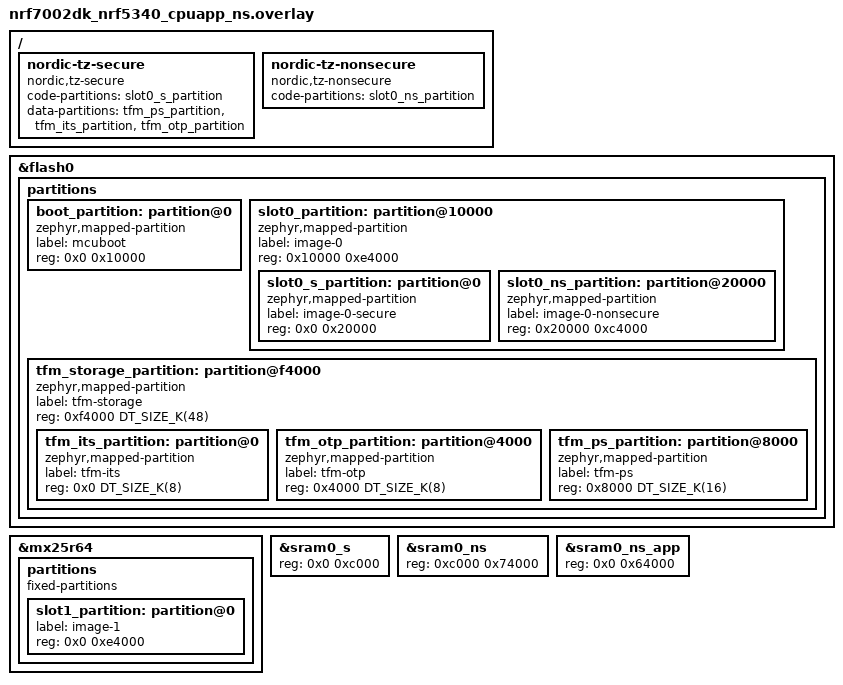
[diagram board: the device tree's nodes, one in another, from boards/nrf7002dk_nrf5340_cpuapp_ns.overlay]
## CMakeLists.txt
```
#
# Copyright (c) 2020 Nordic Semiconductor
#
# SPDX-License-Identifier: LicenseRef-Nordic-5-Clause
#

cmake_minimum_required(VERSION 3.20.0)

find_package(Zephyr REQUIRED HINTS $ENV{ZEPHYR_BASE})
project(aws_iot)

# NORDIC SDK APP START
target_sources(app PRIVATE src/main.c)
target_sources(app PRIVATE src/json_payload/json_payload.c)
# NORDIC SDK APP END

zephyr_include_directories(src)
zephyr_include_directories(src/json_payload)
```

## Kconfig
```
#
# Copyright (c) 2020 Nordic Semiconductor ASA
#
# SPDX-License-Identifier: LicenseRef-Nordic-5-Clause
#

menu "AWS IoT Sample Settings"

config AWS_IOT_SAMPLE_APP_VERSION
	string "Application version"
	default "v1.0.0"
	help
	  Application version reported to AWS IoT.

config AWS_IOT_SAMPLE_JSON_MESSAGE_SIZE_MAX
	int "Maximum size of JSON messages"
	default 200
	help
	  Maximum size of JSON messages that are sent to AWS IoT.

config AWS_IOT_SAMPLE_PUBLICATION_INTERVAL_SECONDS
	int "Interval in seconds that the sample will publish data"
	default 60
	help
	  Time interval between each message publication.

config AWS_IOT_SAMPLE_CONNECTION_RETRY_TIMEOUT_SECONDS
	int "Number of seconds between each AWS IoT connection retry"
	default 30
	help
	  If the connection fails or is lost, the sample tries to reconnect at this interval.

config AWS_IOT_SAMPLE_DEVICE_ID_USE_HW_ID
	bool "Use HW ID as device ID"
	depends on HW_ID_LIBRARY
	help
	  Use the hardware ID as the device ID in the MQTT connection.
	  The hardware ID source is selected by the HW_ID_LIBRARY_SOURCE choice.

module = AWS_IOT_SAMPLE
module-str = AWS IoT sample
source "$(ZEPHYR_BASE)/subsys/logging/Kconfig.template.log_config"

endmenu

menu "Zephyr Kernel"
source "Kconfig.zephyr"
endmenu
```

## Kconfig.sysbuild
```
#
# Copyright (c) 2024 Nordic Semiconductor
#
# SPDX-License-Identifier: LicenseRef-Nordic-5-Clause
#

choice BOOTLOADER
	default BOOTLOADER_MCUBOOT if !BOARD_NATIVE_SIM && \
		!BOARD_NRF54H20DK_NRF54H20_CPUAPP && \
		!BOARD_NRF54LM20DK_NRF54LM20A_CPUAPP && \
		!BOARD_NRF54LM20DK_NRF54LM20B_CPUAPP
endchoice

config WIFI_NRF70
	default y if BOARD_NRF7002DK_NRF5340_CPUAPP_NS || \
		BOARD_NRF54H20DK_NRF54H20_CPUAPP || \
		BOARD_NRF54LM20DK_NRF54LM20A_CPUAPP || \
		BOARD_NRF54LM20DK_NRF54LM20B_CPUAPP

source "share/sysbuild/Kconfig"
```

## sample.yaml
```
sample:
  name: AWS IoT sample
tests:
  sample.net.aws_iot:
    sysbuild: true
    tags:
      - ci_build
      - sysbuild
      - ci_samples_net
    build_only: true
    build_on_all: true
    integration_platforms:
      - nrf9151dk/nrf9151/ns
      - thingy91x/nrf9151/ns
      - native_sim
    platform_allow:
      - nrf9151dk/nrf9151/ns
      - thingy91x/nrf9151/ns
      - native_sim
  sample.net.aws_iot.wifi:
    sysbuild: true
    tags:
      - ci_build
      - sysbuild
      - ci_samples_net
    build_only: true
    build_on_all: true
    integration_platforms:
      - nrf7002dk/nrf5340/cpuapp/ns
      - nrf7120dk/nrf7120/cpuapp/ns
    platform_allow:
      - nrf7002dk/nrf5340/cpuapp/ns
      - nrf7120dk/nrf7120/cpuapp/ns
    extra_args:
      - aws_iot_EXTRA_CONF_FILE="wifi.conf"
  sample.net.aws_iot.nrf7002eb2.wifi:
    sysbuild: true
    tags:
      - ci_build
      - sysbuild
      - ci_samples_net
    build_only: true
    build_on_all: true
    integration_platforms:
      - nrf54lm20dk/nrf54lm20a/cpuapp
      - nrf54lm20dk/nrf54lm20b/cpuapp
    platform_allow:
      - nrf54lm20dk/nrf54lm20a/cpuapp
      - nrf54lm20dk/nrf54lm20b/cpuapp
    extra_args:
      - aws_iot_SHIELD="nrf7002eb2"
      - aws_iot_SNIPPET="nrf70-wifi;wifi-credentials"
      - aws_iot_EXTRA_CONF_FILE="wifi.conf"
```

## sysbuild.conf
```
#
# Copyright (c) 2024 Nordic Semiconductor ASA
#
# SPDX-License-Identifier: LicenseRef-Nordic-5-Clause
#
```

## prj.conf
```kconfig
#
# Copyright (c) 2020 Nordic Semiconductor ASA
#
# SPDX-License-Identifier: LicenseRef-Nordic-5-Clause
#

# General
CONFIG_LOG=y
CONFIG_HW_ID_LIBRARY=y
CONFIG_ASSERT=y
CONFIG_JSON_LIBRARY=y
CONFIG_REBOOT=y

# Heap and stacks
CONFIG_HEAP_MEM_POOL_SIZE=8192
CONFIG_MAIN_STACK_SIZE=4096
CONFIG_SYSTEM_WORKQUEUE_STACK_SIZE=2048

# Network
CONFIG_NETWORKING=y
CONFIG_NET_NATIVE=y
CONFIG_NET_IPV4=y
CONFIG_NET_CONNECTION_MANAGER=y

# AWS IoT library
CONFIG_AWS_IOT=y
CONFIG_AWS_IOT_CLIENT_ID_STATIC="my-thing"
CONFIG_AWS_IOT_BROKER_HOST_NAME="xxx.amazonaws.com"
CONFIG_AWS_IOT_TOPIC_UPDATE_DELTA_SUBSCRIBE=y
CONFIG_AWS_IOT_TOPIC_GET_ACCEPTED_SUBSCRIBE=y
CONFIG_AWS_IOT_TOPIC_GET_REJECTED_SUBSCRIBE=y

# MQTT helper library
CONFIG_MQTT_HELPER=y
CONFIG_MQTT_HELPER_SEC_TAG=201
CONFIG_MQTT_HELPER_LAST_WILL=y
CONFIG_MQTT_HELPER_STACK_SIZE=4096

# MQTT - Maximum MQTT keepalive timeout specified by AWS IoT Core
CONFIG_MQTT_KEEPALIVE=1200
CONFIG_MQTT_CLEAN_SESSION=y
```

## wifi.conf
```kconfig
#
# Copyright (c) 2026 Nordic Semiconductor ASA
#
# SPDX-License-Identifier: LicenseRef-Nordic-5-Clause
#

# Common Wi-Fi + networking + TLS configuration shared by all Wi-Fi builds of
# this sample (nRF70 and nRF71).

# Logging
CONFIG_NET_LOG=y

# Wi-Fi stack
CONFIG_WIFI=y
CONFIG_WIFI_NM_WPA_SUPPLICANT=y
CONFIG_NET_L2_ETHERNET=y
CONFIG_WIFI_NM_WPA_SUPPLICANT_LOG_LEVEL_INF=y

# Wi-Fi credentials. TF-M (_ns) builds use PSA Protected Storage. Non-TF-M
# builds use the Settings subsystem, requiring the wifi-credentials snippet.
CONFIG_WIFI_CREDENTIALS=y
CONFIG_FLASH=y

# Zephyr NET Connection Manager Connectivity layer.
CONFIG_L2_WIFI_CONNECTIVITY=y
CONFIG_L2_WIFI_CONNECTIVITY_AUTO_CONNECT=n
CONFIG_L2_WIFI_CONNECTIVITY_AUTO_DOWN=n

# Networking
CONFIG_NET_SOCKETS=y
CONFIG_NET_SOCKETS_OFFLOAD=n
CONFIG_NET_IPV6=y
CONFIG_NET_UDP=y
CONFIG_NET_TCP=y
CONFIG_NET_DHCPV4=y
CONFIG_NET_CONTEXT_SNDTIMEO=y
CONFIG_NET_CONTEXT_RCVTIMEO=y

# DNS
CONFIG_DNS_RESOLVER=y
CONFIG_NET_SOCKETS_DNS_TIMEOUT=30000
CONFIG_DNS_RESOLVER_AI_MAX_ENTRIES=4

# Shell
CONFIG_SHELL=y
CONFIG_SHELL_CMDS_RESIZE=n
CONFIG_NET_L2_WIFI_SHELL=y

# POSIX API memory optimizations
CONFIG_POSIX_NETWORKING=y
CONFIG_POSIX_FD_MGMT=n
CONFIG_POSIX_MESSAGE_PASSING=n
CONFIG_POSIX_THREAD_THREADS_MAX=0

# Network resource sizing
CONFIG_NET_MAX_CONN=6
CONFIG_NET_MAX_CONTEXTS=5
CONFIG_ZVFS_POLL_MAX=8
CONFIG_NET_PKT_TX_COUNT=6
CONFIG_NET_PKT_RX_COUNT=6
CONFIG_NET_BUF_TX_COUNT=12
CONFIG_NET_BUF_RX_COUNT=6

# Stack sizes
CONFIG_MAIN_STACK_SIZE=6144
CONFIG_SHELL_STACK_SIZE=8192
CONFIG_SYSTEM_WORKQUEUE_STACK_SIZE=8192
CONFIG_NET_TX_STACK_SIZE=4096
CONFIG_NET_RX_STACK_SIZE=2048
CONFIG_NET_SOCKETS_SERVICE_STACK_SIZE=2048

# Heap sizes
CONFIG_HEAP_MEM_POOL_IGNORE_MIN=y
CONFIG_HEAP_MEM_POOL_SIZE=40144
CONFIG_NRF_WIFI_DATA_HEAP_SIZE=65536

# Floating-point printf support (Wi-Fi shell prints PHY TX rate as %f)
CONFIG_CBPRINTF_FP_SUPPORT=y

# NET sockets TLS
CONFIG_NET_SOCKETS_SOCKOPT_TLS=y
CONFIG_NET_SOCKETS_TLS_MAX_CONTEXTS=2

# Generate the device private key and the certificate signing request (CSR) on the device. The
# private key never leaves the device. The device certificate is installed with the TLS
# credentials shell. A credential buffer that fits a certificate chain is needed to install
# the PEM certificates with nrfcredstore.
CONFIG_MQTT_HELPER_CREDENTIALS_KEYGEN=y
CONFIG_TLS_CREDENTIALS_SHELL_CRED_BUF_SIZE=4096
CONFIG_TLS_CREDENTIALS=y
# Persist TLS credentials across reboots.
CONFIG_TLS_CREDENTIALS_BACKEND_PROTECTED_STORAGE=y

# Native network stack
CONFIG_MBEDTLS=y
CONFIG_MBEDTLS_ENABLE_HEAP=y
CONFIG_MBEDTLS_HEAP_SIZE=81920
CONFIG_MBEDTLS_SSL_KEEP_PEER_CERTIFICATE=n
CONFIG_MBEDTLS_SSL_SERVER_NAME_INDICATION=y
# Set MPI (Multiple Precision Integer) size limit to 512 bytes for handling of 4 kb certificates
# in cryptographic operations.
CONFIG_MBEDTLS_MPI_MAX_SIZE=512
# PSA crypto not covered by the ciphersuite: ECDSA for server cert chain verification
CONFIG_PSA_WANT_ALG_ECDSA=y
# TLS crypto via one ciphersuite config
CONFIG_MBEDTLS_CIPHERSUITE_TLS_ECDHE_RSA_WITH_AES_128_GCM_SHA256=y
```

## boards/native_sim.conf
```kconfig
#
# Copyright (c) 2023 Nordic Semiconductor ASA
#
# SPDX-License-Identifier: LicenseRef-Nordic-5-Clause
#

# Networking config
CONFIG_NET_TCP=y
CONFIG_NET_UDP=y
CONFIG_NET_SOCKETS=y
CONFIG_POSIX_API=y
CONFIG_NET_SOCKETS_SOCKOPT_TLS=y
CONFIG_NET_PKT_RX_COUNT=32
CONFIG_NET_PKT_TX_COUNT=32
CONFIG_NET_BUF_RX_COUNT=32
CONFIG_NET_BUF_TX_COUNT=32
CONFIG_NET_IF_UNICAST_IPV6_ADDR_COUNT=3
CONFIG_NET_IF_MCAST_IPV6_ADDR_COUNT=4
CONFIG_NET_MAX_CONTEXTS=10
CONFIG_NET_L2_ETHERNET=y
CONFIG_NET_CONTEXT_SNDTIMEO=y

CONFIG_ETH_NATIVE_TAP=y

# Network driver config
CONFIG_TEST_RANDOM_GENERATOR=y

# TLS configuration
CONFIG_MBEDTLS=y
CONFIG_MBEDTLS_ENABLE_HEAP=y
CONFIG_MBEDTLS_HEAP_SIZE=40000
CONFIG_MBEDTLS_SSL_MAX_CONTENT_LEN=7168
CONFIG_MBEDTLS_PEM_PARSE_C=y
CONFIG_MBEDTLS_PEM_WRITE_C=y
CONFIG_MBEDTLS_CIPHERSUITE_TLS_ECDHE_RSA_WITH_AES_128_CBC_SHA256=y

# DNS
CONFIG_DNS_RESOLVER=y
CONFIG_DNS_SERVER_IP_ADDRESSES=y
CONFIG_DNS_SERVER1="8.8.8.8"
CONFIG_DNS_RESOLVER_MAX_SERVERS=2

# Network address config
CONFIG_NET_CONFIG_SETTINGS=y
CONFIG_NET_CONFIG_NEED_IPV4=y
CONFIG_NET_CONFIG_MY_IPV4_ADDR="192.0.2.1"
CONFIG_NET_CONFIG_MY_IPV4_GW="192.0.2.2"
```

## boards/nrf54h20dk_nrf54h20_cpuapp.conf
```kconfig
#
# Copyright (c) 2024 Nordic Semiconductor ASA
#
# SPDX-License-Identifier: LicenseRef-Nordic-5-Clause
#

# Wi-Fi
CONFIG_WIFI=y
CONFIG_WIFI_NRF70=y
CONFIG_WIFI_CREDENTIALS=y
# Needed for Wi-Fi credentials
CONFIG_FLASH=y
CONFIG_FLASH_PAGE_LAYOUT=y
CONFIG_FLASH_MAP=y
CONFIG_ZMS=y
CONFIG_SETTINGS=y

# WPA supplicant
CONFIG_WIFI_NM_WPA_SUPPLICANT=y
CONFIG_WIFI_NM_WPA_SUPPLICANT_LOG_LEVEL_INF=y

# Networking
CONFIG_NET_L2_ETHERNET=y
CONFIG_NET_SOCKETS=y
CONFIG_NET_IPV6=y
CONFIG_NET_UDP=y
CONFIG_NET_TCP=y
CONFIG_NET_DHCPV4=y
CONFIG_DNS_RESOLVER=y
CONFIG_DNS_RESOLVER_AI_MAX_ENTRIES=4

# NET sockets
CONFIG_NET_UDP=y
CONFIG_NET_TCP=y
CONFIG_NET_MAX_CONN=6
CONFIG_NET_MAX_CONTEXTS=5
CONFIG_NET_SOCKETS_POLL_MAX=8
CONFIG_NET_SOCKETS_OFFLOAD=n
CONFIG_NET_DHCPV4=y
CONFIG_NET_CONTEXT_SNDTIMEO=y
CONFIG_NET_CONTEXT_RCVTIMEO=y
CONFIG_NET_MAX_CONTEXTS=3

# NET buffers
CONFIG_NET_PKT_TX_COUNT=6
CONFIG_NET_PKT_RX_COUNT=6
CONFIG_NET_BUF_TX_COUNT=12
CONFIG_NET_BUF_RX_COUNT=6
CONFIG_NRF70_RX_NUM_BUFS=6
CONFIG_NET_PKT_BUF_RX_DATA_POOL_SIZE=4096
CONFIG_NET_PKT_BUF_TX_DATA_POOL_SIZE=4096
CONFIG_NRF70_MAX_TX_AGGREGATION=1

# MQTT
CONFIG_MQTT_HELPER_PROVISION_CERTIFICATES=y

# Kernel options
CONFIG_POSIX_NETWORKING=y
CONFIG_ZVFS_OPEN_MAX=21

# Shell
CONFIG_SHELL=y
CONFIG_SHELL_CMDS_RESIZE=n
CONFIG_NET_L2_WIFI_SHELL=y

# TLS
CONFIG_NET_SOCKETS_SOCKOPT_TLS=y
CONFIG_NET_SOCKETS_TLS_MAX_CONTEXTS=1
CONFIG_MBEDTLS=y
CONFIG_MBEDTLS_ENABLE_HEAP=y
CONFIG_MBEDTLS_SSL_KEEP_PEER_CERTIFICATE=n
CONFIG_MBEDTLS_SSL_SERVER_NAME_INDICATION=y
CONFIG_TLS_CREDENTIALS=y
CONFIG_TLS_CREDENTIALS_BACKEND_VOLATILE=y

# Zephyr NET Connection Manager Connectivity layer.
CONFIG_L2_WIFI_CONNECTIVITY=y
CONFIG_L2_WIFI_CONNECTIVITY_AUTO_CONNECT=y
CONFIG_L2_WIFI_CONNECTIVITY_AUTO_DOWN=n

# Stack sizes
CONFIG_NET_CONNECTION_MANAGER_MONITOR_STACK_SIZE=5000
CONFIG_MAIN_STACK_SIZE=6144
CONFIG_NET_TX_STACK_SIZE=2048
CONFIG_NET_RX_STACK_SIZE=2048
CONFIG_NET_MGMT_EVENT_STACK_SIZE=1024
CONFIG_SYSTEM_WORKQUEUE_STACK_SIZE=3100
CONFIG_NRF70_IRQ_WQ_STACK_SIZE=1024
CONFIG_NRF70_BH_WQ_STACK_SIZE=2300
CONFIG_SHELL_STACK_SIZE=4400
CONFIG_ISR_STACK_SIZE=512

# Heap sizes
CONFIG_HEAP_MEM_POOL_IGNORE_MIN=y
CONFIG_MBEDTLS_HEAP_SIZE=45000
CONFIG_HEAP_MEM_POOL_SIZE=32000
CONFIG_NRF_WIFI_CTRL_HEAP_SIZE=20000
CONFIG_NRF_WIFI_DATA_HEAP_SIZE=40000

# POSIX API memory optimizations
CONFIG_POSIX_FD_MGMT=n
CONFIG_POSIX_MESSAGE_PASSING=n
CONFIG_POSIX_THREAD_THREADS_MAX=0

# Floating-point printf support
CONFIG_CBPRINTF_FP_SUPPORT=y
```

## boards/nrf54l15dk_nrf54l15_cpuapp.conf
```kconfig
#
# Copyright (c) 2024 Nordic Semiconductor ASA
#
# SPDX-License-Identifier: LicenseRef-Nordic-5-Clause
#

# Wi-Fi
CONFIG_WIFI=y
CONFIG_WIFI_NRF70=y
CONFIG_WIFI_CREDENTIALS=y
# Needed for Wi-Fi credentials
CONFIG_FLASH=y
CONFIG_FLASH_PAGE_LAYOUT=y
CONFIG_FLASH_MAP=y
CONFIG_ZMS=y
CONFIG_SETTINGS=y

# WPA supplicant
CONFIG_WIFI_NM_WPA_SUPPLICANT=y
CONFIG_WIFI_NM_WPA_SUPPLICANT_LOG_LEVEL_INF=y

# Networking
CONFIG_NET_L2_ETHERNET=y
CONFIG_NET_SOCKETS=y
CONFIG_NET_IPV6=y
CONFIG_NET_UDP=y
CONFIG_NET_TCP=y
CONFIG_NET_DHCPV4=y
CONFIG_DNS_RESOLVER=y
CONFIG_DNS_RESOLVER_AI_MAX_ENTRIES=4

# NET sockets
CONFIG_NET_UDP=y
CONFIG_NET_TCP=y
CONFIG_NET_MAX_CONN=6
CONFIG_NET_MAX_CONTEXTS=5
CONFIG_ZVFS_POLL_MAX=8
CONFIG_NET_SOCKETS_OFFLOAD=n
CONFIG_NET_DHCPV4=y
CONFIG_NET_CONTEXT_SNDTIMEO=y
CONFIG_NET_CONTEXT_RCVTIMEO=y
CONFIG_NET_MAX_CONTEXTS=3

# NET buffers
CONFIG_NET_PKT_TX_COUNT=6
CONFIG_NET_PKT_RX_COUNT=6
CONFIG_NET_BUF_TX_COUNT=12
CONFIG_NET_BUF_RX_COUNT=6
CONFIG_NRF70_RX_NUM_BUFS=6
CONFIG_NET_PKT_BUF_RX_DATA_POOL_SIZE=4096
CONFIG_NET_PKT_BUF_TX_DATA_POOL_SIZE=4096
CONFIG_NRF70_MAX_TX_AGGREGATION=1

# MQTT
CONFIG_MQTT_HELPER_PROVISION_CERTIFICATES=y

# Kernel options
CONFIG_POSIX_NETWORKING=y

# Shell
CONFIG_SHELL=y
CONFIG_SHELL_CMDS_RESIZE=n
CONFIG_NET_L2_WIFI_SHELL=y

# TLS
CONFIG_NET_SOCKETS_SOCKOPT_TLS=y
CONFIG_NET_SOCKETS_TLS_MAX_CONTEXTS=1
CONFIG_MBEDTLS=y
CONFIG_MBEDTLS_ENABLE_HEAP=y
CONFIG_MBEDTLS_SSL_KEEP_PEER_CERTIFICATE=n
CONFIG_MBEDTLS_SSL_SERVER_NAME_INDICATION=y
CONFIG_TLS_CREDENTIALS=y
CONFIG_TLS_CREDENTIALS_BACKEND_VOLATILE=y

# Zephyr NET Connection Manager Connectivity layer.
CONFIG_L2_WIFI_CONNECTIVITY=y
CONFIG_L2_WIFI_CONNECTIVITY_AUTO_CONNECT=y
CONFIG_L2_WIFI_CONNECTIVITY_AUTO_DOWN=n

# Stack sizes
CONFIG_MAIN_STACK_SIZE=6144
CONFIG_NET_TX_STACK_SIZE=2048
CONFIG_NET_RX_STACK_SIZE=2048
CONFIG_NET_MGMT_EVENT_STACK_SIZE=1024
CONFIG_SYSTEM_WORKQUEUE_STACK_SIZE=3100
CONFIG_NRF70_IRQ_WQ_STACK_SIZE=1024
CONFIG_NRF70_BH_WQ_STACK_SIZE=2300
CONFIG_SHELL_STACK_SIZE=4400
CONFIG_ISR_STACK_SIZE=512

# Heap sizes
CONFIG_HEAP_MEM_POOL_IGNORE_MIN=y
CONFIG_MBEDTLS_HEAP_SIZE=45000
CONFIG_HEAP_MEM_POOL_SIZE=32000
CONFIG_NRF_WIFI_CTRL_HEAP_SIZE=20000
CONFIG_NRF_WIFI_DATA_HEAP_SIZE=40000

# POSIX API memory optimizations
CONFIG_POSIX_FD_MGMT=n
CONFIG_POSIX_MESSAGE_PASSING=n
CONFIG_POSIX_THREAD_THREADS_MAX=0

# Floating-point printf support
CONFIG_CBPRINTF_FP_SUPPORT=y
```

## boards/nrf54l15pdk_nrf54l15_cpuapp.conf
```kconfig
#
# Copyright (c) 2024 Nordic Semiconductor ASA
#
# SPDX-License-Identifier: LicenseRef-Nordic-5-Clause
#

# Wi-Fi
CONFIG_WIFI=y
CONFIG_WIFI_NRF700X=y

# WPA supplicant
CONFIG_WPA_SUPP=y
CONFIG_WPA_SUPP_LOG_LEVEL_INF=y
CONFIG_NET_L2_WIFI_SHELL=y

# Networking
CONFIG_NET_L2_ETHERNET=y
CONFIG_NETWORKING=y
CONFIG_NET_SOCKETS=y
CONFIG_NET_IPV6=y
CONFIG_NET_IPV4=y
CONFIG_NET_UDP=y
CONFIG_NET_TCP=y
CONFIG_NET_DHCPV4=y
CONFIG_DNS_RESOLVER=y
CONFIG_DNS_RESOLVER_AI_MAX_ENTRIES=4




# NET sockets
CONFIG_NET_UDP=y
CONFIG_NET_TCP=y
CONFIG_NET_MAX_CONN=6
CONFIG_NET_MAX_CONTEXTS=5
CONFIG_NET_SOCKETS_POLL_MAX=8
CONFIG_NET_SOCKETS_OFFLOAD=n
CONFIG_NET_DHCPV4=y
CONFIG_NET_CONTEXT_SNDTIMEO=y
CONFIG_NET_CONTEXT_RCVTIMEO=y

# Below section is the primary contributor to SRAM and is currently
# tuned for performance, but this will be revisited in the future.
CONFIG_NET_BUF_RX_COUNT=16
CONFIG_NET_BUF_TX_COUNT=16
CONFIG_NET_BUF_DATA_SIZE=128
CONFIG_NRF700X_RX_NUM_BUFS=16
CONFIG_NRF700X_MAX_TX_AGGREGATION=4
# nRF700x is main consumer: (16 + 8) * 1600 = ~40KB + ~40KB control path (experimental)
CONFIG_NET_TC_TX_COUNT=1

# MQTT
CONFIG_MQTT_HELPER_PROVISION_CERTIFICATES=y

# Kernel options
CONFIG_REBOOT=y
CONFIG_POSIX_API=y
CONFIG_POSIX_MAX_FDS=25

# Shell
CONFIG_SHELL=y
CONFIG_SHELL_CMDS_RESIZE=n

# Logging
CONFIG_NET_CONFIG_AUTO_INIT=n

# TLS
CONFIG_NET_SOCKETS_SOCKOPT_TLS=y
CONFIG_NET_SOCKETS_TLS_MAX_CONTEXTS=2
CONFIG_NRF_SECURITY=y
CONFIG_MBEDTLS=y
CONFIG_MBEDTLS_ENABLE_HEAP=y
CONFIG_MBEDTLS_SSL_KEEP_PEER_CERTIFICATE=n
CONFIG_MBEDTLS_SSL_SERVER_NAME_INDICATION=y
CONFIG_TLS_CREDENTIALS=y
CONFIG_TLS_CREDENTIALS_BACKEND_VOLATILE=y

# Stack sizes
CONFIG_NET_CONNECTION_MANAGER_MONITOR_STACK_SIZE=4096
CONFIG_NET_TX_STACK_SIZE=2048
CONFIG_NET_RX_STACK_SIZE=2048
CONFIG_NET_MGMT_EVENT_STACK_SIZE=1024
CONFIG_SYSTEM_WORKQUEUE_STACK_SIZE=2300
CONFIG_NRF700X_IRQ_WQ_STACK_SIZE=1024
CONFIG_NRF700X_BH_WQ_STACK_SIZE=2300
CONFIG_MQTT_HELPER_STACK_SIZE=4096
CONFIG_SHELL_STACK_SIZE=4400

# Heap sizes
CONFIG_COMMON_LIBC_MALLOC_ARENA_SIZE=21808
CONFIG_MBEDTLS_HEAP_SIZE=54920
CONFIG_HEAP_MEM_POOL_SIZE=80000

# Bootloader requirements
CONFIG_BOOTLOADER_MCUBOOT=y
CONFIG_FLASH=y
CONFIG_FLASH_PAGE_LAYOUT=y
CONFIG_FLASH_MAP=y
CONFIG_STREAM_FLASH=y
CONFIG_STREAM_FLASH_ERASE=y
CONFIG_IMG_MANAGER=y
CONFIG_MCUBOOT_IMG_MANAGER=y
CONFIG_FW_INFO_OFFSET=0x800

# AWS FOTA
CONFIG_AWS_FOTA=y
CONFIG_FOTA_DOWNLOAD=y
CONFIG_DFU_TARGET=y

# Download client (needed by AWS FOTA)
CONFIG_DOWNLOAD_CLIENT=y
CONFIG_DOWNLOAD_CLIENT_STACK_SIZE=4096
CONFIG_DOWNLOAD_CLIENT_BUF_SIZE=4096
CONFIG_DOWNLOAD_CLIENT_HTTP_FRAG_SIZE_4096=y

# Disable connection manager
CONFIG_NET_CONNECTION_MANAGER=n
```

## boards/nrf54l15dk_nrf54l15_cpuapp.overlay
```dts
/*
 * Copyright (c) 2024 Nordic Semiconductor ASA
 *
 * SPDX-License-Identifier: LicenseRef-Nordic-5-Clause
 */

&rram_controller {
	/delete-node/ cpuflpr_sram;
	/delete-node/ cpuflpr_rram;
};

/* Adjust the cpuapp_sram to include the freed up cpuflpr_sram */
&cpuapp_sram {
	reg = <0x20000000 DT_SIZE_K(256)>;
	ranges = <0x0 0x20000000 0x20040000>;
};

/* Adjust the cpuapp_rram to include the freed up cpuflpr_rram */
&cpuapp_rram {
	reg = <0x0 DT_SIZE_K(1524)>;
};
```

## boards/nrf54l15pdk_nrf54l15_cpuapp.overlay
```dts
/*
 * Copyright (c) 2024 Nordic Semiconductor ASA
 *
 * SPDX-License-Identifier: LicenseRef-Nordic-5-Clause
 */

/ {
	/* Configure the partition manager to use the mx25r64 external flash memory. */
	chosen {
		nordic,pm-ext-flash = &mx25r64;
	};
};

&mx25r64 {
	status = "okay";
};

/* Restore full RRAM and SRAM space - by default some parts are dedicated to VPR */
&cpuapp_rram {
	reg = <0x0 DT_SIZE_K(1524)>;
};

&cpuapp_sram {
	reg = <0x20000000 DT_SIZE_K(256)>;
	ranges = <0x0 0x20000000  0x40000>;
};
```

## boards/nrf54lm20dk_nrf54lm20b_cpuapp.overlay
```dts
/*
 * Copyright (c) 2026 Nordic Semiconductor ASA
 *
 * SPDX-License-Identifier: LicenseRef-Nordic-5-Clause
 */

/delete-node/ &boot_partition;
/delete-node/ &slot0_partition;
/delete-node/ &slot1_partition;
/delete-node/ &storage_partition;

&cpuapp_rram {
	partitions {
		slot0_partition: partition@0 {
			compatible = "zephyr,mapped-partition";
			label = "image-0";
			reg = <0x0 0x1f5000>;
		};

		storage_partition: partition@1f5000 {
			compatible = "zephyr,mapped-partition";
			label = "storage";
			reg = <0x1f5000 0x8000>;
		};
	};
};
```

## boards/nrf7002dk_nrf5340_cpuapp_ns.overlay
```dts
/*
 * Copyright (c) 2023 Nordic Semiconductor ASA
 *
 * SPDX-License-Identifier: LicenseRef-Nordic-5-Clause
 */

/delete-node/ &boot_partition;
/delete-node/ &slot0_partition;
/delete-node/ &slot1_partition;
/delete-node/ &tfm_its_partition;
/delete-node/ &tfm_otp_partition;
/delete-node/ &tfm_ps_partition;
/delete-node/ &storage_partition;

&flash0 {
	partitions {
		boot_partition: partition@0 {
			compatible = "zephyr,mapped-partition";
			label = "mcuboot";
			reg = <0x0 0x10000>;
		};

		slot0_partition: partition@10000 {
			compatible = "zephyr,mapped-partition";
			label = "image-0";
			reg = <0x10000 0xe4000>;
			ranges = <0x0 0x10000 0xe4000>;
			#address-cells = <1>;
			#size-cells = <1>;

			slot0_s_partition: partition@0 {
				compatible = "zephyr,mapped-partition";
				label = "image-0-secure";
				reg = <0x0 0x20000>;
			};

			slot0_ns_partition: partition@20000 {
				compatible = "zephyr,mapped-partition";
				label = "image-0-nonsecure";
				reg = <0x20000 0xc4000>;
			};
		};

		tfm_storage_partition: partition@f4000 {
			compatible = "zephyr,mapped-partition";
			label = "tfm-storage";
			reg = <0xf4000 DT_SIZE_K(48)>;
			ranges = <0x0 0xf4000 DT_SIZE_K(48)>;
			#address-cells = <1>;
			#size-cells = <1>;

			tfm_its_partition: partition@0 {
				compatible = "zephyr,mapped-partition";
				label = "tfm-its";
				reg = <0x0 DT_SIZE_K(8)>;
			};

			tfm_otp_partition: partition@4000 {
				compatible = "zephyr,mapped-partition";
				label = "tfm-otp";
				reg = <0x4000 DT_SIZE_K(8)>;
			};

			tfm_ps_partition: partition@8000 {
				compatible = "zephyr,mapped-partition";
				label = "tfm-ps";
				reg = <0x8000 DT_SIZE_K(16)>;
			};
		};
	};
};

&mx25r64 {
	status = "okay";

	partitions {
		compatible = "fixed-partitions";
		#address-cells = <1>;
		#size-cells = <1>;

		slot1_partition: partition@0 {
			label = "image-1";
			reg = <0x0 0xe4000>;
		};
	};
};

/*
 * TrustZone SRAM split from devicetree (region_defs.h for TF-M). The secure image uses
 * 48 KiB (0xc000) at the base of cpuapp SRAM (&sram0_s); NS RAM begins at 0x20000000 + 0xc000.
 * &sram0_ns spans 0x74000 bytes; &sram0_ns_app is 0x64000 because the top 0x10000 (64 KiB)
 * within that NS window is sram0_shared for application/network-core IPC
 * (nrf5340_shared_sram_partition.dtsi), i.e. 0x64000 + 0x10000 == 0x74000.
 */
&sram0_s {
	reg = <0x0 0xc000>;
};

&sram0_ns {
	reg = <0xc000 0x74000>;
	ranges = <0x0 0xc000 0x74000>;
};

&sram0_ns_app {
	reg = <0x0 0x64000>;
};

/ {
	/delete-node/ nordic-tz-secure;
	/delete-node/ nordic-tz-nonsecure;

	nordic-tz-secure {
		compatible = "nordic,tz-secure";
		code-partitions = <&slot0_s_partition>;
		data-partitions = <&tfm_ps_partition>,
				  <&tfm_its_partition>,
				  <&tfm_otp_partition>;
	};

	nordic-tz-nonsecure {
		compatible = "nordic,tz-nonsecure";
		code-partitions = <&slot0_ns_partition>;
	};
};
```

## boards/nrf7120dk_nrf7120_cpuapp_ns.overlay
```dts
/*
 * Copyright (c) 2026 Nordic Semiconductor ASA
 *
 * SPDX-License-Identifier: LicenseRef-Nordic-5-Clause
 */

&cpuapp_mram {
	/delete-node/ partitions;
};

&cpuapp_mram {
	/*
	 * Default NVM layout on NRF7120 NS Application MCU with MCUBoot:
	 *
	 * 0x0000_0000 Boot Partition (64 KB)
	 *
	 * 0x0001_0000 Primary image area (1952 KB):
	 *   - 0x0001_0000 Secure image primary (192 KB)
	 *   - 0x0004_0000 Non-secure image primary (1760 KB)
	 *
	 * 0x001F_8000 Secondary image area (1952 KB):
	 *   - 0x001F_8000 Secure image secondary (192 KB)
	 *   - 0x0022_8000 Non-secure image secondary (1760 KB)
	 *
	 * 0x003E_0000 Protected Storage Area (16 KB)
	 * 0x003E_4000 Internal Trusted Storage Area (16 KB)
	 * 0x003E_8000 OTP / NV counters area (8 KB)
	 *
	 * 0x003E_A000 Non-secure storage, used when built with NRF_NS_STORAGE=ON,
	 *             otherwise unused (68 KB)
	 */
	partitions {
		#address-cells = <1>;
		#size-cells = <1>;
		ranges;

		boot_partition: partition@0 {
			compatible = "zephyr,mapped-partition";
			label = "mcuboot";
			reg = <0x00000000 DT_SIZE_K(64)>;
		};

		slot0_partition: partition@10000 {
			compatible = "zephyr,mapped-partition";
			label = "image-0";
			reg = <0x00010000 DT_SIZE_K(1952)>;
			ranges = <0x0 0x00010000 DT_SIZE_K(1952)>;
			#address-cells = <1>;
			#size-cells = <1>;

			slot0_s_partition: partition@0 {
				compatible = "zephyr,mapped-partition";
				label = "image-0-secure";
				reg = <0x0 DT_SIZE_K(192)>;
			};

			slot0_ns_partition: partition@30000 {
				compatible = "zephyr,mapped-partition";
				label = "image-0-nonsecure";
				reg = <0x30000 DT_SIZE_K(1760)>;
			};
		};

		slot1_partition: partition@1f8000 {
			compatible = "zephyr,mapped-partition";
			label = "image-1";
			reg = <0x001f8000 DT_SIZE_K(1952)>;
			ranges = <0x0 0x001f8000 DT_SIZE_K(1952)>;
			#address-cells = <1>;
			#size-cells = <1>;

			slot1_s_partition: partition@0 {
				compatible = "zephyr,mapped-partition";
				label = "image-1-secure";
				reg = <0x0 DT_SIZE_K(192)>;
			};

			slot1_ns_partition: partition@30000 {
				compatible = "zephyr,mapped-partition";
				label = "image-1-nonsecure";
				reg = <0x30000 DT_SIZE_K(1760)>;
			};
		};

		tfm_ps_partition: partition@3e0000 {
			compatible = "zephyr,mapped-partition";
			label = "tfm-ps";
			reg = <0x003e0000 DT_SIZE_K(16)>;
		};

		tfm_its_partition: partition@3e4000 {
			compatible = "zephyr,mapped-partition";
			label = "tfm-its";
			reg = <0x003e4000 DT_SIZE_K(16)>;
		};

		tfm_otp_partition: partition@3e8000 {
			compatible = "zephyr,mapped-partition";
			label = "tfm-otp";
			reg = <0x003e8000 DT_SIZE_K(8)>;
		};

		storage_partition: partition@3ea000 {
			compatible = "zephyr,mapped-partition";
			label = "storage";
			reg = <0x003ea000 DT_SIZE_K(68)>;
		};
	};
};

/ {
	chosen {
		zephyr,code-partition = &slot0_ns_partition;
	};
};
```

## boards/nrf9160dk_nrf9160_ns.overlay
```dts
/*
 * Copyright (c) 2023 Nordic Semiconductor ASA
 *
 * SPDX-License-Identifier: LicenseRef-Nordic-5-Clause
 */

#include <samples/cellular/nrf91_bootloader_partitions.dtsi>

#include <samples/cellular/nrf91_sram_partitions.dtsi>

/* Enable uart1 for tracing. */
&uart1 {
	status = "okay";
	current-speed = <1000000>;
};

/ {
	chosen {
		nordic,modem-trace-uart = &uart1;
	};
};

/* Increase modem (shared) memory and add trace partition. */
&sram0_ns_modem {
	reg = <0x0 0x8800>;
	ranges = <0x0 0x0 0x8800>;

	cpucell_cpuapp_ipc_shm_trace: sram0_ns_modem@4800 {
		/* Modem trace memory */
		reg = <0x4800 0x4000>;
	};
};

/* Delete Non-Secure application memory so we can move and shrink it. */
/delete-node/ &sram0_ns_app;

&sram0_ns {
	sram0_ns_app: sram0_ns@8800 {
		/* Redefine smaller Non-Secure application memory. */
		reg = <0x8800 0x2f800>;
	};
};
```

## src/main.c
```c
/*
 * Copyright (c) 2020 Nordic Semiconductor ASA
 *
 * SPDX-License-Identifier: LicenseRef-Nordic-5-Clause
 */

#include <zephyr/kernel.h>
#include <zephyr/sys/reboot.h>
#include <zephyr/dfu/mcuboot.h>
#include <zephyr/logging/log.h>
#include <zephyr/logging/log_ctrl.h>
#include <zephyr/net/conn_mgr_connectivity.h>
#include <net/aws_iot.h>
#include <stdio.h>
#include <stdlib.h>
#include <hw_id.h>
#include <modem/modem_info.h>

#include "json_payload.h"

/* Register log module */
LOG_MODULE_REGISTER(aws_iot_sample, CONFIG_AWS_IOT_SAMPLE_LOG_LEVEL);

/* Macros used to subscribe to specific Zephyr NET management events. */
#define L4_EVENT_MASK (NET_EVENT_L4_DNS_READY | NET_EVENT_L4_DNS_LOST)
#define CONN_LAYER_EVENT_MASK (NET_EVENT_CONN_IF_FATAL_ERROR)

#define MODEM_FIRMWARE_VERSION_SIZE_MAX 50

/* Application specific topics. */
#define MY_CUSTOM_TOPIC_1 "my-custom-topic/example"
#define MY_CUSTOM_TOPIC_2 "my-custom-topic/example_2"

/* Macro called upon a fatal error, reboots the device. */
#define FATAL_ERROR()					\
	LOG_ERR("Fatal error! Rebooting the device.");	\
	LOG_PANIC();					\
	IF_ENABLED(CONFIG_REBOOT, (sys_reboot(0)))

/* Variable used to store the device's hardware ID. */
static char hw_id[HW_ID_LEN];

/* Forward declarations. */
static void shadow_update_work_fn(struct k_work *work);
static void connect_work_fn(struct k_work *work);
static void aws_iot_event_handler(const struct aws_iot_evt *const evt);

/* Work items used to control some aspects of the sample. */
static K_WORK_DELAYABLE_DEFINE(shadow_update_work, shadow_update_work_fn);
static K_WORK_DELAYABLE_DEFINE(connect_work, connect_work_fn);

/* Static functions */

static int app_topics_subscribe(void)
{
	int err;
	static const struct mqtt_topic topic_list[] = {
		{
			.topic.utf8 = MY_CUSTOM_TOPIC_1,
			.topic.size = sizeof(MY_CUSTOM_TOPIC_1) - 1,
			.qos = MQTT_QOS_1_AT_LEAST_ONCE,
		},
		{
			.topic.utf8 = MY_CUSTOM_TOPIC_2,
			.topic.size = sizeof(MY_CUSTOM_TOPIC_2) - 1,
			.qos = MQTT_QOS_1_AT_LEAST_ONCE,
		}
	};

	err = aws_iot_application_topics_set(topic_list, ARRAY_SIZE(topic_list));
	if (err) {
		LOG_ERR("aws_iot_application_topics_set, error: %d", err);
		FATAL_ERROR();
		return err;
	}

	return 0;
}

static int aws_iot_client_init(void)
{
	int err;

	err = aws_iot_init(aws_iot_event_handler);
	if (err) {
		LOG_ERR("AWS IoT library could not be initialized, error: %d", err);
		FATAL_ERROR();
		return err;
	}

	/* Add application specific non-shadow topics to the AWS IoT library.
	 * These topics will be subscribed to when connecting to the broker.
	 */
	err = app_topics_subscribe();
	if (err) {
		LOG_ERR("Adding application specific topics failed, error: %d", err);
		FATAL_ERROR();
		return err;
	}

	return 0;
}

/* System Workqueue handlers. */

static void shadow_update_work_fn(struct k_work *work)
{
	int err;
	char message[CONFIG_AWS_IOT_SAMPLE_JSON_MESSAGE_SIZE_MAX] = { 0 };
	struct payload payload = {
		.state.reported.uptime = k_uptime_get(),
		.state.reported.app_version = CONFIG_AWS_IOT_SAMPLE_APP_VERSION,
	};
	struct aws_iot_data tx_data = {
		.qos = MQTT_QOS_0_AT_MOST_ONCE,
		.topic.type = AWS_IOT_SHADOW_TOPIC_UPDATE,
	};

	if (IS_ENABLED(CONFIG_MODEM_INFO)) {
		char modem_version_temp[MODEM_FIRMWARE_VERSION_SIZE_MAX];

		err = modem_info_get_fw_version(modem_version_temp,
						ARRAY_SIZE(modem_version_temp));
		if (err) {
			LOG_ERR("modem_info_get_fw_version, error: %d", err);
			FATAL_ERROR();
			return;
		}

		payload.state.reported.modem_version = modem_version_temp;
	}

	err = json_payload_construct(message, sizeof(message), &payload);
	if (err) {
		LOG_ERR("json_payload_construct, error: %d", err);
		FATAL_ERROR();
		return;
	}

	tx_data.ptr = message;
	tx_data.len = strlen(message);

	LOG_INF("Publishing message: %s to AWS IoT shadow", message);

	err = aws_iot_send(&tx_data);
	if (err) {
		LOG_ERR("aws_iot_send, error: %d", err);
		FATAL_ERROR();
		return;
	}

	(void)k_work_reschedule(&shadow_update_work,
				K_SECONDS(CONFIG_AWS_IOT_SAMPLE_PUBLICATION_INTERVAL_SECONDS));
}

static void connect_work_fn(struct k_work *work)
{
	int err;
	const struct aws_iot_config config = {
		.client_id = hw_id,
	};

	LOG_INF("Connecting to AWS IoT");

	err = aws_iot_connect(&config);
	if (err == -EAGAIN) {
		LOG_INF("Connection attempt timed out, "
			"Next connection retry in %d seconds",
			CONFIG_AWS_IOT_SAMPLE_CONNECTION_RETRY_TIMEOUT_SECONDS);

		(void)k_work_reschedule(&connect_work,
				K_SECONDS(CONFIG_AWS_IOT_SAMPLE_CONNECTION_RETRY_TIMEOUT_SECONDS));
	} else if (err) {
		LOG_ERR("aws_iot_connect, error: %d", err);
		FATAL_ERROR();
	}
}

/* Functions that are executed on specific connection-related events. */

static void on_aws_iot_evt_connected(const struct aws_iot_evt *const evt)
{
	(void)k_work_cancel_delayable(&connect_work);

	/* If persistent session is enabled, the AWS IoT library will not subscribe to any topics.
	 * Topics from the last session will be used.
	 */
	if (evt->data.persistent_session) {
		LOG_WRN("Persistent session is enabled, using subscriptions "
			"from the previous session");
	}

	/* Mark image as working to avoid reverting to the former image after a reboot. */
	if (IS_ENABLED(CONFIG_BOOTLOADER_MCUBOOT)) {
		boot_write_img_confirmed();
	}

	/* Start sequential updates to AWS IoT. */
	(void)k_work_reschedule(&shadow_update_work, K_NO_WAIT);
}

static void on_aws_iot_evt_disconnected(void)
{
	(void)k_work_cancel_delayable(&shadow_update_work);
	(void)k_work_reschedule(&connect_work, K_SECONDS(5));
}

static void on_aws_iot_evt_fota_done(const struct aws_iot_evt *const evt)
{
	int err;

	/* Tear down MQTT connection. */
	(void)aws_iot_disconnect();
	(void)k_work_cancel_delayable(&connect_work);

	/* If modem FOTA has been carried out, the modem needs to be reinitialized.
	 * This is carried out by bringing the network interface down/up.
	 */
	if (evt->data.image & DFU_TARGET_IMAGE_TYPE_ANY_MODEM) {
		LOG_INF("Modem FOTA done, reinitializing the modem");

		err = conn_mgr_all_if_down(true);
		if (err) {
			LOG_ERR("conn_mgr_all_if_down, error: %d", err);
			FATAL_ERROR();
			return;
		}

		err = conn_mgr_all_if_up(true);
		if (err) {
			LOG_ERR("conn_mgr_all_if_up, error: %d", err);
			FATAL_ERROR();
			return;
		}

		err = conn_mgr_all_if_connect(true);
		if (err) {
			LOG_ERR("conn_mgr_all_if_connect, error: %d", err);
			FATAL_ERROR();
			return;
		}

	} else if (evt->data.image & DFU_TARGET_IMAGE_TYPE_ANY_APPLICATION) {
		LOG_INF("Application FOTA done, rebooting");
		log_flush();
		LOG_PANIC();
		IF_ENABLED(CONFIG_REBOOT, (sys_reboot(0)));
	} else {
		LOG_WRN("Unexpected FOTA image type");
	}
}

static void on_net_event_l4_connected(void)
{
	(void)k_work_reschedule(&connect_work, K_SECONDS(5));
}

static void on_net_event_l4_disconnected(void)
{
	(void)aws_iot_disconnect();
	(void)k_work_cancel_delayable(&connect_work);
	(void)k_work_cancel_delayable(&shadow_update_work);
}

/* Event handlers */

static void aws_iot_event_handler(const struct aws_iot_evt *const evt)
{
	switch (evt->type) {
	case AWS_IOT_EVT_CONNECTING:
		LOG_INF("AWS_IOT_EVT_CONNECTING");
		break;
	case AWS_IOT_EVT_CONNECTED:
		LOG_INF("AWS_IOT_EVT_CONNECTED");
		on_aws_iot_evt_connected(evt);
		break;
	case AWS_IOT_EVT_DISCONNECTED:
		LOG_INF("AWS_IOT_EVT_DISCONNECTED");
		on_aws_iot_evt_disconnected();
		break;
	case AWS_IOT_EVT_DATA_RECEIVED:
		LOG_INF("AWS_IOT_EVT_DATA_RECEIVED");

		LOG_INF("Received message: \"%.*s\" on topic: \"%.*s\"", evt->data.msg.len,
									 evt->data.msg.ptr,
									 evt->data.msg.topic.len,
									 evt->data.msg.topic.str);
		break;
	case AWS_IOT_EVT_PUBACK:
		LOG_INF("AWS_IOT_EVT_PUBACK, message ID: %d", evt->data.message_id);
		break;
	case AWS_IOT_EVT_PINGRESP:
		LOG_INF("AWS_IOT_EVT_PINGRESP");
		break;
	case AWS_IOT_EVT_FOTA_START:
		LOG_INF("AWS_IOT_EVT_FOTA_START");
		break;
	case AWS_IOT_EVT_FOTA_ERASE_PENDING:
		LOG_INF("AWS_IOT_EVT_FOTA_ERASE_PENDING");
		break;
	case AWS_IOT_EVT_FOTA_ERASE_DONE:
		LOG_INF("AWS_FOTA_EVT_ERASE_DONE");
		break;
	case AWS_IOT_EVT_FOTA_DONE:
		LOG_INF("AWS_IOT_EVT_FOTA_DONE");
		on_aws_iot_evt_fota_done(evt);
		break;
	case AWS_IOT_EVT_FOTA_DL_PROGRESS:
		LOG_INF("AWS_IOT_EVT_FOTA_DL_PROGRESS, (%d%%)", evt->data.fota_progress);
		break;
	case AWS_IOT_EVT_ERROR:
		LOG_INF("AWS_IOT_EVT_ERROR, %d", evt->data.err);
		FATAL_ERROR();
		break;
	case AWS_IOT_EVT_FOTA_ERROR:
		LOG_INF("AWS_IOT_EVT_FOTA_ERROR");
		break;
	default:
		LOG_WRN("Unknown AWS IoT event type: %d", evt->type);
		break;
	}
}

static void l4_event_handler(uint64_t event, struct net_if *iface, void *info,
			     size_t info_length, void *user_data)
{
	switch (event) {
	case NET_EVENT_L4_DNS_READY:
		LOG_INF("Network connectivity established");
		on_net_event_l4_connected();
		break;
	case NET_EVENT_L4_DNS_LOST:
		LOG_INF("Network connectivity lost");
		on_net_event_l4_disconnected();
		break;
	default:
		/* Don't care */
		return;
	}
}

static void connectivity_event_handler(uint64_t event, struct net_if *iface, void *info,
				       size_t info_length, void *user_data)
{
	if (event == NET_EVENT_CONN_IF_FATAL_ERROR) {
		LOG_ERR("NET_EVENT_CONN_IF_FATAL_ERROR");
		FATAL_ERROR();
		return;
	}
}

/* Registered statically to not miss events raised before main() */
NET_MGMT_REGISTER_EVENT_HANDLER(l4_events, L4_EVENT_MASK, l4_event_handler, NULL);
NET_MGMT_REGISTER_EVENT_HANDLER(conn_events, CONN_LAYER_EVENT_MASK, connectivity_event_handler,
				NULL);

int main(void)
{
	LOG_INF("The AWS IoT sample started, version: %s", CONFIG_AWS_IOT_SAMPLE_APP_VERSION);

	int err;

	/* Connecting to the configured connectivity layer.
	 * Wi-Fi or LTE depending on the board that the sample was built for.
	 */
	LOG_INF("Bringing network interface up and connecting to the network");

	err = conn_mgr_all_if_up(true);
	if (err) {
		LOG_ERR("conn_mgr_all_if_up, error: %d", err);
		FATAL_ERROR();
		return err;
	}

	err = conn_mgr_all_if_connect(true);
	if (err) {
		LOG_ERR("conn_mgr_all_if_connect, error: %d", err);
		FATAL_ERROR();
		return err;
	}

	if (IS_ENABLED(CONFIG_AWS_IOT_SAMPLE_DEVICE_ID_USE_HW_ID)) {
		/* Get unique hardware ID, can be used as AWS IoT MQTT broker device/client ID. */
		err = hw_id_get(hw_id, ARRAY_SIZE(hw_id));
		if (err) {
			LOG_ERR("Failed to retrieve hardware ID, error: %d", err);
			FATAL_ERROR();
			return err;
		}

		LOG_INF("Hardware ID: %s", hw_id);
	}

	err = aws_iot_client_init();
	if (err) {
		LOG_ERR("aws_iot_client_init, error: %d", err);
		FATAL_ERROR();
		return err;
	}

	return 0;
}
```
